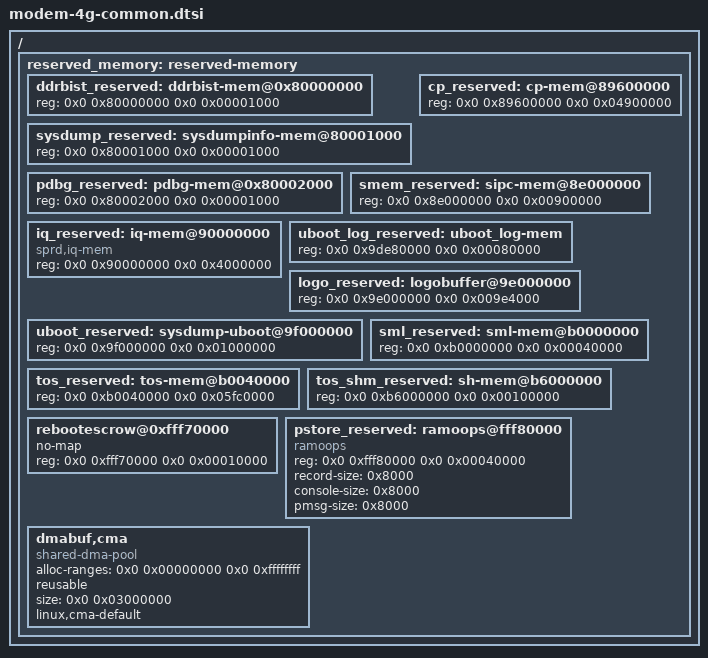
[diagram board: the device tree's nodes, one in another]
/ {
	reserved_memory: reserved-memory {
		#address-cells = <2>;
		#size-cells = <2>;
		ranges;

		ddrbist_reserved: ddrbist-mem@0x80000000 {
			reg = <0x0 0x80000000 0x0 0x00001000>;
		};

		sysdump_reserved: sysdumpinfo-mem@80001000 {
			reg = <0x0 0x80001000 0x0 0x00001000>;
		};

		pdbg_reserved: pdbg-mem@0x80002000 {
			reg = <0x0 0x80002000 0x0 0x00001000>;
		};

		cp_reserved: cp-mem@89600000 {
			reg = <0x0 0x89600000 0x0 0x04900000>;
		};


		smem_reserved: sipc-mem@8e000000 {
			reg = <0x0 0x8e000000 0x0 0x00900000>;
		};

		/* Only used for iq, will be removed in normal mode by uboot */
		iq_reserved: iq-mem@90000000 {
			compatible = "sprd,iq-mem";
			reg = <0x0 0x90000000 0x0 0x4000000>;
		};

		/* The uboot_log_reserved node is added in uboot. base:0x9de8 0000, size:0x80000 */
		uboot_log_reserved: uboot_log-mem {
			reg = <0x0 0x9de80000 0x0 0x00080000>;
		};

		logo_reserved: logobuffer@9e000000 {
			reg = <0x0 0x9e000000 0x0 0x009e4000>;
		};

		/* Only for userdebug, will be removed in user mode by uboot */
		uboot_reserved: sysdump-uboot@9f000000 {
			reg = <0x0 0x9f000000 0x0 0x01000000>;
		};

		sml_reserved: sml-mem@b0000000 {
			reg = <0x0 0xb0000000 0x0 0x00040000>;
		};

		tos_reserved: tos-mem@b0040000 {
			reg = <0x0 0xb0040000 0x0 0x05fc0000>;
		};

		tos_shm_reserved: sh-mem@b6000000 {
			reg = <0x0 0xb6000000 0x0 0x00100000>;
		};

		rebootescrow@0xfff70000 {
			no-map;
			reg = <0x0 0xfff70000 0x0 0x00010000>; /* 64K */
		};

		pstore_reserved: ramoops@fff80000 {
			compatible = "ramoops";
			reg = <0x0 0xfff80000 0x0 0x00040000>;
			record-size = <0x8000>;
			console-size = <0x8000>;
			pmsg-size = <0x8000>;
		};

		/* global autoconfigured region for contiguous allocations */
		dmabuf,cma {
			compatible = "shared-dma-pool";
			alloc-ranges = <0x0 0x00000000 0x0 0xffffffff>;
			reusable;
			size = <0x0 0x03000000>;
			linux,cma-default;
		};
	};
};
